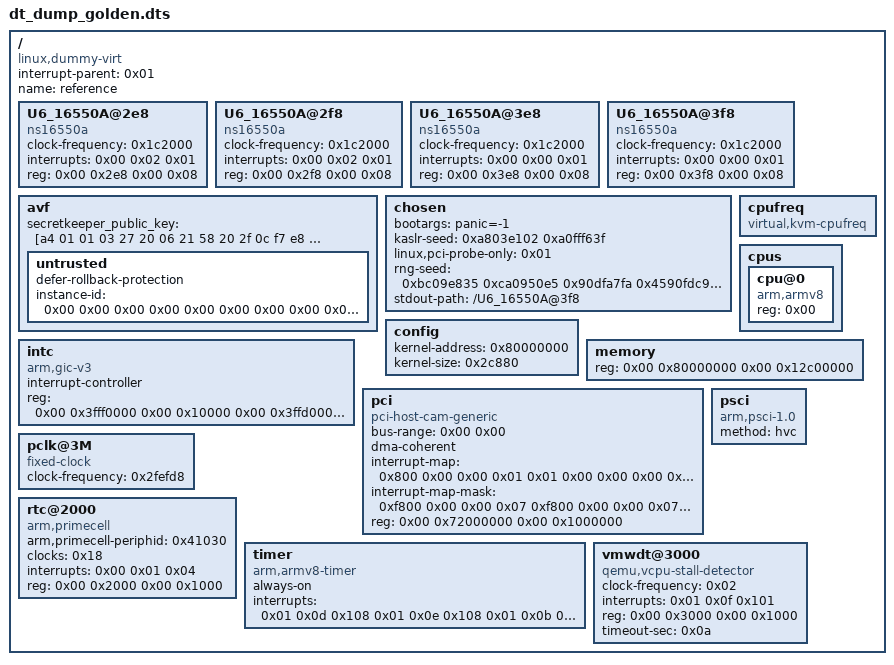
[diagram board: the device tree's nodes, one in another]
/dts-v1/;

/ {
	#address-cells = <0x02>;
	#size-cells = <0x02>;
	compatible = "linux,dummy-virt";
	interrupt-parent = <0x01>;
	name = "reference";

	U6_16550A@2e8 {
		clock-frequency = <0x1c2000>;
		compatible = "ns16550a";
		interrupts = <0x00 0x02 0x01>;
		reg = <0x00 0x2e8 0x00 0x08>;
	};

	U6_16550A@2f8 {
		clock-frequency = <0x1c2000>;
		compatible = "ns16550a";
		interrupts = <0x00 0x02 0x01>;
		reg = <0x00 0x2f8 0x00 0x08>;
	};

	U6_16550A@3e8 {
		clock-frequency = <0x1c2000>;
		compatible = "ns16550a";
		interrupts = <0x00 0x00 0x01>;
		reg = <0x00 0x3e8 0x00 0x08>;
	};

	U6_16550A@3f8 {
		clock-frequency = <0x1c2000>;
		compatible = "ns16550a";
		interrupts = <0x00 0x00 0x01>;
		reg = <0x00 0x3f8 0x00 0x08>;
	};

	__symbols__ {
		intc = "/intc";
	};

	avf {
		secretkeeper_public_key = [a4 01 01 03 27 20 06 21 58 20 2f 0c f7 e8 a1 ab 24 b5 96 c5 12 0f 85 d0 31 a7 ae f4 21 5b 95 b8 26 7d 32 39 18 c1 c0 29 e4 1f];

		untrusted {
			defer-rollback-protection;
			instance-id = <0x00 0x00 0x00 0x00 0x00 0x00 0x00 0x00 0x00 0x00 0x00 0x00 0x00 0x00 0x00 0x00>;
		};
	};

	chosen {
		bootargs = "panic=-1";
		kaslr-seed = <0xa803e102 0xa0fff63f>;
		linux,pci-probe-only = <0x01>;
		rng-seed = <0xbc09e835 0xca0950e5 0x90dfa7fa 0x4590fdc9 0x6a308717 0xe44f045a 0x9be57093 0x9628cbf5 0x5ef152a4 0x4c06b06e 0x4ad10d33 0x4e5f6a4f 0x9958ba8c 0x3e890845 0x3e41ae6 0x1a1a6529 0xd1e057ad 0x9ea14958 0x2736de9 0x61cf62cc 0x57e52ee9 0x1bcb3012 0xc2c6ec45 0x4922a6d6 0x60614ef0 0xd24c3fce 0x18c9da6b 0x20532e5 0xa964be66 0x301f9141 0x199a33d8 0x412cf19c 0xbaaee968 0x19ddf1ab 0x57a5c099 0x3ece1d91 0x965321c0 0xb8de8146 0xdc3717cb 0x64dfc7b2 0x5e7575a2 0x2901439d 0x155e7134 0x28d77b30 0x5ed8748 0x3b6b27a6 0xefa0599 0x3f43acd3 0x212d662e 0x9d5aec3 0xed4e5c8d 0x6e39da77 0x7a5dfeeb 0xf9fa0929 0xb5643a24 0x6cc68a42 0x969234b3 0x7871e61 0x94c1669f 0xe496c044 0x421ba747 0xd6aa70b1 0x3d7d1019 0xf439a365>;
		stdout-path = "/U6_16550A@3f8";
	};

	config {
		kernel-address = <0x80000000>;
		kernel-size = <0x2c880>;
	};

	cpufreq {
		compatible = "virtual,kvm-cpufreq";
	};

	cpus {
		#address-cells = <0x01>;
		#size-cells = <0x00>;

		cpu@0 {
			compatible = "arm,armv8";
			device_type = "cpu";
			phandle = <0x100>;
			reg = <0x00>;
		};
	};

	intc {
		#address-cells = <0x02>;
		#interrupt-cells = <0x03>;
		#size-cells = <0x02>;
		compatible = "arm,gic-v3";
		interrupt-controller;
		phandle = <0x01>;
		reg = <0x00 0x3fff0000 0x00 0x10000 0x00 0x3ffd0000 0x00 0x20000>;
	};

	memory {
		device_type = "memory";
		reg = <0x00 0x80000000 0x00 0x12c00000>;
	};

	pci {
		#address-cells = <0x03>;
		#interrupt-cells = <0x01>;
		#size-cells = <0x02>;
		bus-range = <0x00 0x00>;
		compatible = "pci-host-cam-generic";
		device_type = "pci";
		dma-coherent;
		interrupt-map = <0x800 0x00 0x00 0x01 0x01 0x00 0x00 0x00 0x04 0x04 0x1000 0x00 0x00 0x01 0x01 0x00 0x00 0x00 0x05 0x04 0x1800 0x00 0x00 0x01 0x01 0x00 0x00 0x00 0x06 0x04 0x2000 0x00 0x00 0x01 0x01 0x00 0x00 0x00 0x07 0x04 0x2800 0x00 0x00 0x01 0x01 0x00 0x00 0x00 0x08 0x04 0x3000 0x00 0x00 0x01 0x01 0x00 0x00 0x00 0x09 0x04 0x3800 0x00 0x00 0x01 0x01 0x00 0x00 0x00 0x0a 0x04 0x4000 0x00 0x00 0x01 0x01 0x00 0x00 0x00 0x0b 0x04>;
		interrupt-map-mask = <0xf800 0x00 0x00 0x07 0xf800 0x00 0x00 0x07 0xf800 0x00 0x00 0x07 0xf800 0x00 0x00 0x07 0xf800 0x00 0x00 0x07 0xf800 0x00 0x00 0x07 0xf800 0x00 0x00 0x07 0xf800 0x00 0x00 0x07>;
		ranges = <0x3000000 0x00 0x70000000 0x00 0x70000000 0x00 0x2000000 0x43000000 0x00 0x93400000 0x00 0x93400000 0xff 0x6cc00000>;
		reg = <0x00 0x72000000 0x00 0x1000000>;
	};

	pclk@3M {
		#clock-cells = <0x00>;
		clock-frequency = <0x2fefd8>;
		compatible = "fixed-clock";
		phandle = <0x18>;
	};

	psci {
		compatible = "arm,psci-1.0\0arm,psci-0.2";
		method = "hvc";
	};

	rtc@2000 {
		arm,primecell-periphid = <0x41030>;
		clock-names = "apb_pclk";
		clocks = <0x18>;
		compatible = "arm,primecell";
		interrupts = <0x00 0x01 0x04>;
		reg = <0x00 0x2000 0x00 0x1000>;
	};

	timer {
		always-on;
		compatible = "arm,armv8-timer";
		interrupts = <0x01 0x0d 0x108 0x01 0x0e 0x108 0x01 0x0b 0x108 0x01 0x0a 0x108>;
	};

	vmwdt@3000 {
		clock-frequency = <0x02>;
		compatible = "qemu,vcpu-stall-detector";
		interrupts = <0x01 0x0f 0x101>;
		reg = <0x00 0x3000 0x00 0x1000>;
		timeout-sec = <0x0a>;
	};
};
